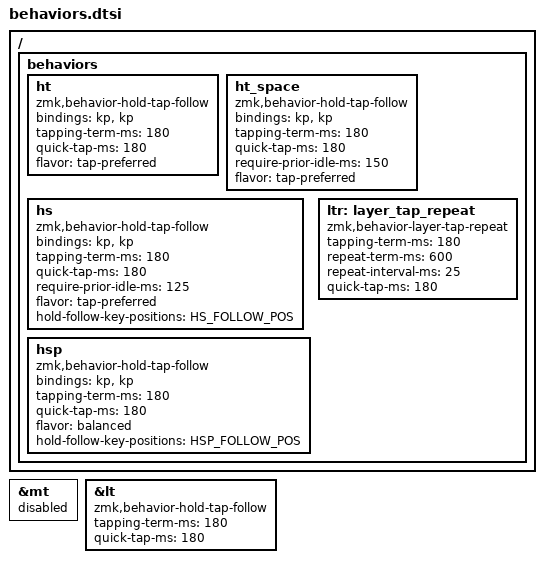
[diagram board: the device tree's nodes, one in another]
// Behaviors shared by every keyboard in this repo (config/corne.keymap, config/cygnus.keymap). Include it
// after defining the key positions the behaviors depend on:
//
//   HS_FOLLOW_POS           position of the A key: ' followed by A is always Shift+A
//   HSP_FOLLOW_POS          position of the / key: Z followed by / is always Shift+/
//
// The layers' keys are in layers.dtsi, and the System layer combo in combos.dtsi.
#include <behaviors.dtsi>
#include <dt-bindings/zmk/bt.h>
#include <dt-bindings/zmk/outputs.h>
#include <dt-bindings/zmk/keys.h>
#include <dt-bindings/zmk/pointing.h>

#define BASE 0
#define NUM 1
#define NAV 2
#define SYS 3

// All hold-taps use zmk,behavior-hold-tap-follow (src/behaviors/behavior_hold_tap_follow.c), a copy of
// ZMK's hold-tap with hold-follow-key-positions. Two hold-tap implementations can't coexist, so the stock
// &lt is switched over and the unused stock &mt is disabled; that keeps ZMK's own copy out of the build.
&mt {
    status = "disabled";
};

// Match QMK: same tapping term, and tap-then-hold repeats the tap key (e.g. Backspace) instead of switching layers.
&lt {
    compatible = "zmk,behavior-hold-tap-follow";
    tapping-term-ms = <180>;
    quick-tap-ms = <180>;
};

/ {
    behaviors {
        // Mod-taps for the thumbs, Q and the Num layer shifts. Tap-preferred like QMK's default mod-tap:
        // the hold only fires after the tapping term, so fast typing never triggers a modifier.
        ht: ht {
            compatible = "zmk,behavior-hold-tap-follow";
            bindings = <&kp>, <&kp>;

            #binding-cells = <2>;
            tapping-term-ms = <180>;
            quick-tap-ms = <180>;
            flavor = "tap-preferred";
        };

        // Space/Gui: like ht, but pressed within 150 ms of typing a key it is always Space, so a
        // fast "<space>t" never becomes Gui+T. Not on the Ctrl/Alt mod-taps, which
        // are often wanted straight after typing (Ctrl+Backspace).
        ht_space: ht_space {
            compatible = "zmk,behavior-hold-tap-follow";
            bindings = <&kp>, <&kp>;

            #binding-cells = <2>;
            tapping-term-ms = <180>;
            quick-tap-ms = <180>;
            require-prior-idle-ms = <150>;
            flavor = "tap-preferred";
        };

        // Shift on A and ': like ht, but pressed within 125 ms of typing a letter it is always
        // the letter, so mid-word rolls ("reassure", "hearing") never shift. To capitalize, pause
        // briefly before holding Shift (it works with either hand, including same-hand letters).
        // ' followed by A is always Shift+A, however fast and whichever is released first, so a
        // quick ' + A chord is "A" rather than "'a" (HS_FOLLOW_POS is the A key; A itself is unaffected).
        hs: hs {
            compatible = "zmk,behavior-hold-tap-follow";
            bindings = <&kp>, <&kp>;

            #binding-cells = <2>;
            tapping-term-ms = <180>;
            quick-tap-ms = <180>;
            require-prior-idle-ms = <125>;
            flavor = "tap-preferred";
            hold-follow-key-positions = <HS_FOLLOW_POS>;
        };

        // Shift on Z and /, the punctuation shifts: often wanted right after a letter ("what?"),
        // so no idle check. Balanced: tapping another key while Z or / is down is Shift+key even
        // if both are released inside 180 ms. Z followed by / is always Shift+/, however fast and
        // whichever is released first, so a quick Z + / chord is "?" rather than "z/" (HSP_FOLLOW_POS is the / key;
        // / itself is unaffected). Other rolls (Z released before the next key) are still letters.
        hsp: hsp {
            compatible = "zmk,behavior-hold-tap-follow";
            bindings = <&kp>, <&kp>;

            #binding-cells = <2>;
            tapping-term-ms = <180>;
            quick-tap-ms = <180>;
            flavor = "balanced";
            hold-follow-key-positions = <HSP_FOLLOW_POS>;
        };

        // Backspace/Nav thumb (custom behavior in src/behaviors/):
        // tap for Backspace; hold for Nav (keys pressed in the first 180 ms wait, like QMK);
        // hold alone for 600 ms and Backspace repeats at 40/s, matching sway's repeat_rate.
        // While Shift, Gui or a letter is held it's only Nav, never Backspace (Ctrl/Alt+Backspace still work).
        ltr: layer_tap_repeat {
            compatible = "zmk,behavior-layer-tap-repeat";
            #binding-cells = <2>;
            tapping-term-ms = <180>;
            repeat-term-ms = <600>;
            repeat-interval-ms = <25>;
            quick-tap-ms = <180>;
        };
    };
};
